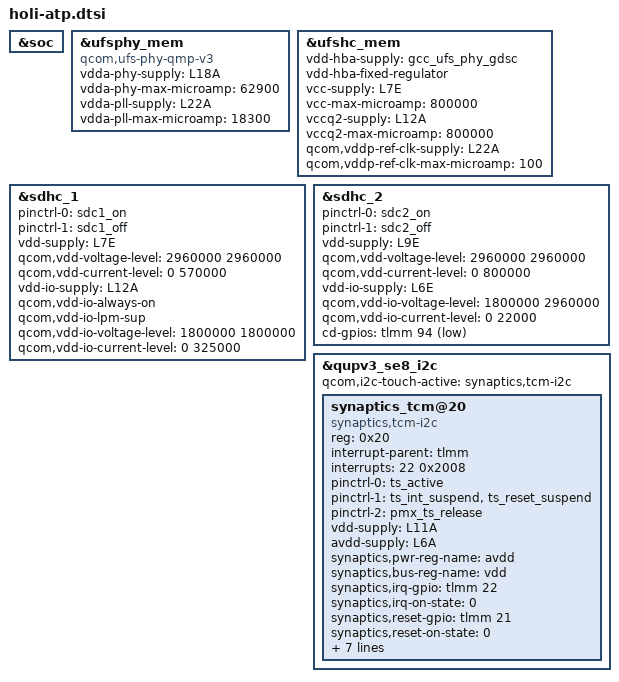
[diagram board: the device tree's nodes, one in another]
#include <dt-bindings/gpio/gpio.h>
#include "holi-atp-pm7250b.dtsi"
#include "holi-thermal-overlay.dtsi"

&soc {

};

&ufsphy_mem {
	compatible = "qcom,ufs-phy-qmp-v3";

	/* VDDA_UFS_CORE */
	vdda-phy-supply = <&L18A>;
	vdda-phy-max-microamp = <62900>;

	/* VDDA_UFS_0_1P2 */
	vdda-pll-supply = <&L22A>;
	vdda-pll-max-microamp = <18300>;

	status = "ok";
};

&ufshc_mem {
	vdd-hba-supply = <&gcc_ufs_phy_gdsc>;
	vdd-hba-fixed-regulator;

	vcc-supply = <&L7E>;
	vcc-max-microamp = <800000>;

	vccq2-supply = <&L12A>;
	vccq2-max-microamp = <800000>;

	qcom,vddp-ref-clk-supply = <&L22A>;
	qcom,vddp-ref-clk-max-microamp = <100>;

	status = "ok";
};

&sdhc_1 {
	status = "ok";

	pinctrl-names = "default", "sleep";
	pinctrl-0 = <&sdc1_on>;
	pinctrl-1 = <&sdc1_off>;

	vdd-supply = <&L7E>;
	qcom,vdd-voltage-level = <2960000 2960000>;
	qcom,vdd-current-level = <0 570000>;

	vdd-io-supply = <&L12A>;
	qcom,vdd-io-always-on;
	qcom,vdd-io-lpm-sup;
	qcom,vdd-io-voltage-level = <1800000 1800000>;
	qcom,vdd-io-current-level = <0 325000>;
};

&sdhc_2 {
	status = "ok";

	pinctrl-names = "default", "sleep";
	pinctrl-0 = <&sdc2_on>;
	pinctrl-1 = <&sdc2_off>;

	vdd-supply = <&L9E>;
	qcom,vdd-voltage-level = <2960000 2960000>;
	qcom,vdd-current-level = <0 800000>;

	vdd-io-supply = <&L6E>;
	qcom,vdd-io-voltage-level = <1800000 2960000>;
	qcom,vdd-io-current-level = <0 22000>;

	cd-gpios = <&tlmm 94 GPIO_ACTIVE_LOW>;
};

&qupv3_se8_i2c {
	status = "okay";
	qcom,i2c-touch-active="synaptics,tcm-i2c";

	synaptics_tcm@20 {
		compatible = "synaptics,tcm-i2c";
		reg = <0x20>;
		interrupt-parent = <&tlmm>;
		interrupts = <22 0x2008>;
		pinctrl-names = "pmx_ts_active","pmx_ts_suspend",
					"pmx_ts_release";
		pinctrl-0 = <&ts_active>;
		pinctrl-1 = <&ts_int_suspend &ts_reset_suspend>;
		pinctrl-2 = <&pmx_ts_release>;
		vdd-supply = <&L11A>;
		avdd-supply = <&L6A>;
		synaptics,pwr-reg-name = "avdd";
		synaptics,bus-reg-name = "vdd";
		synaptics,irq-gpio = <&tlmm 22 0x2008>;
		synaptics,irq-on-state = <0>;
		synaptics,reset-gpio = <&tlmm 21 0x00>;
		synaptics,reset-on-state = <0>;
		synaptics,reset-active-ms = <20>;
		synaptics,reset-delay-ms = <200>;
		synaptics,power-delay-ms = <200>;
		synaptics,ubl-i2c-addr = <0x20>;
		synaptics,extend_report;
		synaptics,firmware-name = "synaptics_firmware.img";
	};
};
